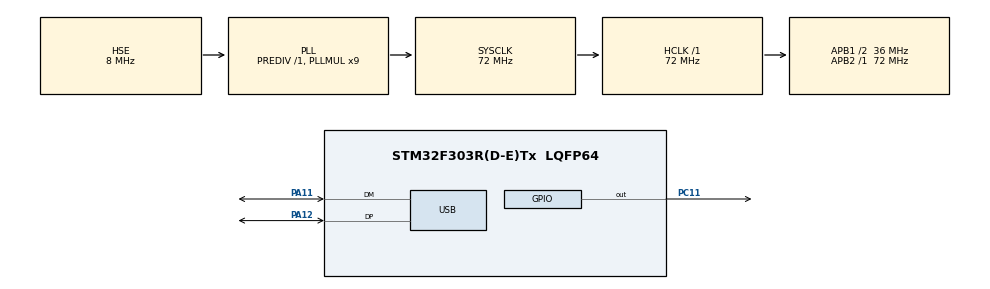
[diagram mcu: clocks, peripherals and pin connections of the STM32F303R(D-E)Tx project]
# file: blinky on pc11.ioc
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Mcu.Family=STM32F3
Mcu.Name=STM32F303R(D-E)Tx
Mcu.Package=LQFP64
NVIC.PriorityGroup=NVIC_PRIORITYGROUP_4
NVIC.USB_LP_CAN_RX0_IRQn=true\:0\:0\:false\:false\:true\:false\:true
PA11.Mode=Device
PA11.Signal=USB_DM
PA12.Mode=Device
PA12.Signal=USB_DP
PC11.Signal=GPIO_Output
PC14-OSC32_IN.Mode=LSE-External-Oscillator
PC14-OSC32_IN.Signal=RCC_OSC32_IN
PC15-OSC32_OUT.Mode=LSE-External-Oscillator
PC15-OSC32_OUT.Signal=RCC_OSC32_OUT
PF0-OSC_IN.Mode=HSE-External-Oscillator
PF0-OSC_IN.Signal=RCC_OSC_IN
PF1-OSC_OUT.Mode=HSE-External-Oscillator
PF1-OSC_OUT.Signal=RCC_OSC_OUT
ProjectManager.HeapSize=0x200
ProjectManager.StackSize=0x400
ProjectManager.TargetToolchain=STM32CubeIDE
RCC.AHBFreq_Value=72000000
RCC.APB1CLKDivider=RCC_HCLK_DIV2
RCC.APB1Freq_Value=36000000
RCC.APB1TimFreq_Value=72000000
RCC.APB2Freq_Value=72000000
RCC.APB2TimFreq_Value=72000000
RCC.CortexFreq_Value=72000000
RCC.HCLKFreq_Value=72000000
RCC.HSE_VALUE=8000000
RCC.HSI_VALUE=8000000
RCC.PLLMUL=RCC_PLL_MUL9
RCC.PRESCALERUSB=RCC_USBCLKSOURCE_PLL_DIV1_5
RCC.SYSCLKFreq_VALUE=72000000
RCC.SYSCLKSourceVirtual=RCC_SYSCLKSOURCE_PLLCLK
RCC.USBFreq_Value=48000000
USB_DEVICE.CLASS_NAME_FS=MSC
USB_DEVICE.VirtualMode=Msc
USB_DEVICE.VirtualModeFS=Msc_FS
VP_USB_DEVICE_VS_USB_DEVICE_MSC_FS.Mode=MSC_FS
board=custom

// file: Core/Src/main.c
/* USER CODE BEGIN Header */
/**
  ******************************************************************************
  * @file           : main.c
  * @brief          : Main program body
  ******************************************************************************
  * @attention
  *
  * Copyright (c) 2024 STMicroelectronics.
  * All rights reserved.
  *
  * This software is licensed under terms that can be found in the LICENSE file
  * in the root directory of this software component.
  * If no LICENSE file comes with this software, it is provided AS-IS.
  *
  ******************************************************************************
  */
/* USER CODE END Header */
#include "main.h"
#include "usb_device.h"

#include "flash_image.h"

void SystemClock_Config(void);
static void MX_GPIO_Init(void);

int main(void)
{

  /* MCU Configuration--------------------------------------------------------*/

  /* Reset of all peripherals, Initializes the Flash interface and the Systick. */
  HAL_Init();

  /* USER CODE BEGIN Init */
  asm("cpsie i");//enable inturrupts
  asm("cpsie f");

  /* USER CODE END Init */

  /* Configure the system clock */
  SystemClock_Config();

  /* USER CODE BEGIN SysInit */
  //RCC->AHBENR |= RCC_AHBENR_GPIOCEN;//enable GPIOC

  /* USER CODE END SysInit */

  /* Initialize all configured peripherals */
  MX_GPIO_Init();
  MX_USB_DEVICE_Init();
  /* USER CODE BEGIN 2 */

  //GPIOC->MODER &= ~(GPIO_MODER_MODER12);//clear bits in MODER register (input mode) corresponding to PC11

  /* USER CODE END 2 */

  /* Infinite loop */
  /* USER CODE BEGIN WHILE */
  while (1)
  {
  	HAL_GPIO_TogglePin(GPIOC, GPIO_PIN_11);
  	HAL_Delay(1000);
    /* USER CODE END WHILE */

  }
}

void SystemClock_Config(void)
{
  RCC_OscInitTypeDef RCC_OscInitStruct = {0};
  RCC_ClkInitTypeDef RCC_ClkInitStruct = {0};
  RCC_PeriphCLKInitTypeDef PeriphClkInit = {0};

  /** Initializes the RCC Oscillators according to the specified parameters
  * in the RCC_OscInitTypeDef structure.
  */
  RCC_OscInitStruct.OscillatorType = RCC_OSCILLATORTYPE_HSE;
  RCC_OscInitStruct.HSEState = RCC_HSE_ON;
  RCC_OscInitStruct.HSIState = RCC_HSI_ON;
  RCC_OscInitStruct.PLL.PLLState = RCC_PLL_ON;
  RCC_OscInitStruct.PLL.PLLSource = RCC_PLLSOURCE_HSE;
  RCC_OscInitStruct.PLL.PLLMUL = RCC_PLL_MUL9;
  RCC_OscInitStruct.PLL.PREDIV = RCC_PREDIV_DIV1;
  if (HAL_RCC_OscConfig(&RCC_OscInitStruct) != HAL_OK)
  {
    Error_Handler();
  }
  /** Initializes the CPU, AHB and APB buses clocks
  */
  RCC_ClkInitStruct.ClockType = RCC_CLOCKTYPE_HCLK|RCC_CLOCKTYPE_SYSCLK
                              |RCC_CLOCKTYPE_PCLK1|RCC_CLOCKTYPE_PCLK2;
  RCC_ClkInitStruct.SYSCLKSource = RCC_SYSCLKSOURCE_PLLCLK;
  RCC_ClkInitStruct.AHBCLKDivider = RCC_SYSCLK_DIV1;
  RCC_ClkInitStruct.APB1CLKDivider = RCC_HCLK_DIV2;
  RCC_ClkInitStruct.APB2CLKDivider = RCC_HCLK_DIV1;

  if (HAL_RCC_ClockConfig(&RCC_ClkInitStruct, FLASH_LATENCY_2) != HAL_OK)
  {
    Error_Handler();
  }
  PeriphClkInit.PeriphClockSelection = RCC_PERIPHCLK_USB;
  PeriphClkInit.USBClockSelection = RCC_USBCLKSOURCE_PLL_DIV1_5;
  if (HAL_RCCEx_PeriphCLKConfig(&PeriphClkInit) != HAL_OK)
  {
    Error_Handler();
  }
}

static void MX_GPIO_Init(void)
{
  GPIO_InitTypeDef GPIO_InitStruct = {0};

  /* GPIO Ports Clock Enable */
  __HAL_RCC_GPIOC_CLK_ENABLE();
  __HAL_RCC_GPIOF_CLK_ENABLE();
  __HAL_RCC_GPIOA_CLK_ENABLE();

  /*Configure GPIO pin Output Level */
  HAL_GPIO_WritePin(GPIOC, GPIO_PIN_11, GPIO_PIN_RESET);

  /*Configure GPIO pin : PC11 */
  GPIO_InitStruct.Pin = GPIO_PIN_11;
  GPIO_InitStruct.Mode = GPIO_MODE_OUTPUT_PP;
  GPIO_InitStruct.Pull = GPIO_NOPULL;
  GPIO_InitStruct.Speed = GPIO_SPEED_FREQ_LOW;
  HAL_GPIO_Init(GPIOC, &GPIO_InitStruct);

}

void Error_Handler(void)
{
  __disable_irq();
  while (1)
  {
  }
}
